# f29h85x_hsm_dthe_crc_p_regs register map
Vendor: Texas Instruments
Peripheral module from a debugger description file (folder HSM).
Registers are 32-bit, read-write, no defined reset value unless marked. A register's access mark holds for its fields unless they carry their own. Offsets are as the file gives them; lines under a group give offsets from that group; [hi:lo] are bit positions; {n}, {i} and the like mark numbered series; 'fields as' and 'values as' point back to an identical list; <NAME> marks a mode.

## HSM_DTHE_CRC_P — HSM DTHE CRC P Registers
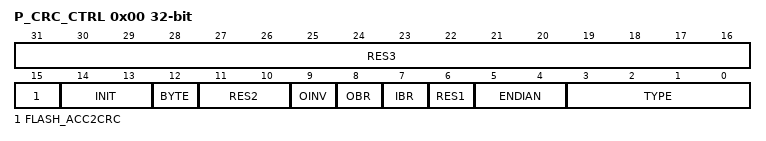
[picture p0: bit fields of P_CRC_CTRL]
0x00 P_CRC_CTRL access per field
  [31:16] RES3 ro, [15] FLASH_ACC2CRC rw, [14:13] INIT rw, [12] BYTE rw, [11:10] RES2 ro, [9] OINV rw, [8] OBR rw, [7] IBR rw, [6] RES1 ro, [5:4] ENDIAN rw, [3:0] TYPE rw
0x20 P_CRC_SEED
0x40 P_CRC_DIN
  [31:0] DATA_IN
0x60 P_CRC_RSLT_PP ro
  [31:0] RSLT_PP
